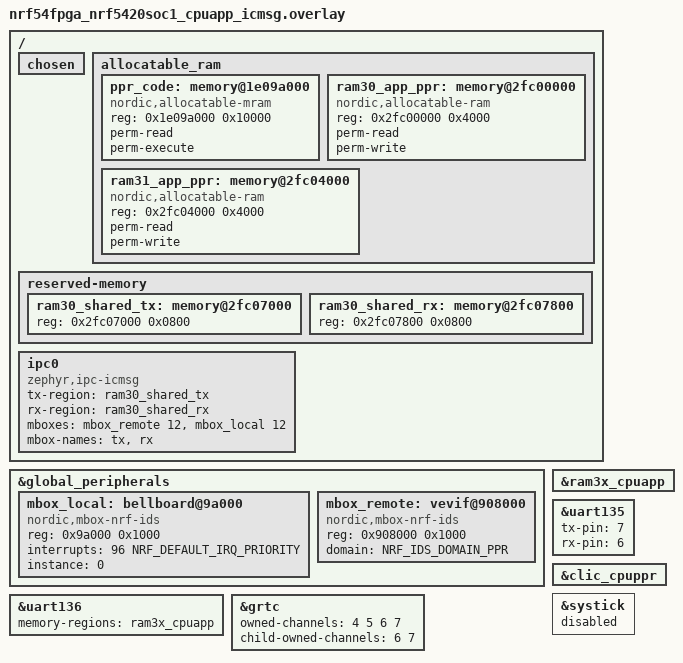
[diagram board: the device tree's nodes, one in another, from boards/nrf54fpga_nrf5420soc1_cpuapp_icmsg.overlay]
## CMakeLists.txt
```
#
# Copyright (c) 2022 Nordic Semiconductor
#
# SPDX-License-Identifier: LicenseRef-Nordic-5-Clause
#

cmake_minimum_required(VERSION 3.20.0)

if(CONF_FILE)
  if(${CONF_FILE} MATCHES "prj_(.*).conf")
    set(CONF_FILE_BUILD_TYPE ${CMAKE_MATCH_1})

    # At this stage, any revision attached to the board will not be available
    # as BOARD_REVISION, just "@<revision>" in the board name. We clean up the
    # path to reflect what the associated overlay/fragment paths are supposed to
    # look like in sample/boards.
    string(REPLACE "@" "_" SAMPLE_BOARD "${BOARD}")

    set(DTC_OVERLAY_FILE "${CMAKE_CURRENT_SOURCE_DIR}/boards/${SAMPLE_BOARD}_${CONF_FILE_BUILD_TYPE}.overlay")
  endif()
  set(remote_CONF_FILE ${CONF_FILE})
endif()

set(ZEPHYR_EXTRA_MODULES ${CMAKE_CURRENT_LIST_DIR})

find_package(Zephyr REQUIRED HINTS $ENV{ZEPHYR_BASE})
project(event_manager_proxy)

message(STATUS "Overlay set to: ${DTC_OVERLAY_FILE}")

add_subdirectory(common_events)
add_subdirectory(modules)

target_sources(app PRIVATE src/main.c)

if (CONFIG_SOC_PLATFORM_HALTIUM)
  build_secdom()
  build_sysctrl()
endif()
```

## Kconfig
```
#
# Copyright (c) 2022 Nordic Semiconductor ASA
#
# SPDX-License-Identifier: LicenseRef-Nordic-5-Clause
#

menu "Zephyr Kernel"
source "Kconfig.zephyr"
endmenu

menu "Event manager proxy sample application settings"

config APP_EVENT_MANAGER_REMOTE_WAIT_TO
	int "Waiting period for the remote core to finish the initialization"
	range 10 5000
	default 1000
	help
	  The time to wait for second core to report its readines to transport the events.
	  The time is given in miliseconds.

config APP_INCLUDE_REMOTE_IMAGE
	bool "Include remote image as sub image"
	depends on SOC_NRF5340_CPUAPP || SOC_NRF54H20_CPUAPP || SOC_NRF9230_CPUAPP
	default y if (BOARD_NRF5340DK_NRF5340_CPUAPP || BOARD_NRF5340DK_NRF5340_CPUAPP_NS || BOARD_NRF54H20DK_NRF54H20_CPUAPP || BOARD_NRF9230DK_NRF9230_CPUAPP)
	select PARTITION_MANAGER_ENABLED if SOC_NRF5340_CPUAPP
	select BOARD_ENABLE_CPUNET if (BOARD_NRF5340DK_NRF5340_CPUAPP || BOARD_NRF5340DK_NRF5340_CPUAPP_NS)

config APP_REMOTE_BOARD
	string "The name of the CORE to be used by remote image"
	depends on APP_INCLUDE_REMOTE_IMAGE
	default DOMAIN_CPUNET_BOARD if (BOARD_NRF5340DK_NRF5340_CPUAPP || BOARD_NRF5340DK_NRF5340_CPUAPP_NS)
	default "nrf54h20dk_nrf54h20_cpuppr@soc1" if (BOARD_NRF54H20DK_NRF54H20_CPUAPP && HW_REVISION_SOC1)
	default "nrf9230dk_nrf9230_cpuppr" if (BOARD_NRF9230DK_NRF9230_CPUAPP)

rsource "common_events/Kconfig"
rsource "modules/Kconfig"
endmenu
```

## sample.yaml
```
sample:
  description: Sample showing usage of sending the events to another core via Event Manager Proxy
  name: Event Manager proxy sample
tests:
  sample.event_manager_proxy:
    build_only: true
    platform_allow: nrf5340dk_nrf5340_cpuapp
    integration_platforms:
      - nrf5340dk_nrf5340_cpuapp
    tags: ci_build
  sample.event_manager_proxy.icmsg:
    build_only: true
    platform_allow: nrf5340dk_nrf5340_cpuapp
    integration_platforms:
      - nrf5340dk_nrf5340_cpuapp
    tags: ci_build
    extra_args: CONF_FILE=prj_icmsg.conf
  sample.event_manager_proxy.nrf54h20.fpga.icmsg:
    build_only: true
    platform_allow: nrf54h20dk_nrf54h20_cpuapp@soc1
    integration_platforms:
      - nrf54h20dk_nrf54h20_cpuapp@soc1
    tags: ci_build
    extra_args: CONF_FILE=prj_icmsg.conf remote_CONFIG_EMULATOR_FPGA=y
    extra_configs:
      - CONFIG_EMULATOR_FPGA=y
  sample.event_manager_proxy.nrf54h20.icmsg:
    build_only: true
    platform_allow: nrf54h20dk_nrf54h20_cpuapp@soc1
    integration_platforms:
      - nrf54h20dk_nrf54h20_cpuapp@soc1
    tags: ci_build
    extra_args: CONF_FILE=prj_icmsg.conf
  sample.event_manager_proxy.nrf9230.fpga.icmsg:
    build_only: true
    platform_allow: nrf9230dk_nrf9230_cpuapp
    integration_platforms:
      - nrf9230dk_nrf9230_cpuapp
    tags: ci_build
    extra_args: CONF_FILE=prj_icmsg.conf remote_CONFIG_EMULATOR_FPGA=y
    extra_configs:
      - CONFIG_EMULATOR_FPGA=y
```

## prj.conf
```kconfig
#
# Copyright (c) 2022 Nordic Semiconductor ASA
#
# SPDX-License-Identifier: LicenseRef-Nordic-5-Clause
#
# Enabling assert
CONFIG_ASSERT=y

# Logger configuration
CONFIG_SERIAL=y
CONFIG_CONSOLE=y
CONFIG_LOG=y
CONFIG_LOG_DEFAULT_LEVEL=2
CONFIG_LOG_BACKEND_UART=y

# Configuration required by Event Manager
CONFIG_APP_EVENT_MANAGER=y
CONFIG_EVENT_MANAGER_PROXY=y
CONFIG_HEAP_MEM_POOL_SIZE=4096
CONFIG_REBOOT=y

CONFIG_PRINTK=y

CONFIG_IPC_SERVICE=y
CONFIG_MBOX=y

CONFIG_OPENAMP=y
CONFIG_OPENAMP_SLAVE=n

# Simplify debugging
CONFIG_RESET_ON_FATAL_ERROR=n

###################################
# Application configuration
###################################

CONFIG_APP_CONFIG_EVENT=y
CONFIG_APP_MODULE_STATS_ENABLE=y
```

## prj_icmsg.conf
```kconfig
#
# Copyright (c) 2022 Nordic Semiconductor ASA
#
# SPDX-License-Identifier: LicenseRef-Nordic-5-Clause
#
# Enabling assert
CONFIG_ASSERT=y

# Logger configuration
CONFIG_SERIAL=y
CONFIG_CONSOLE=y
CONFIG_LOG=y
CONFIG_LOG_DEFAULT_LEVEL=2
CONFIG_LOG_BACKEND_UART=y

# Configuration required by Event Manager
CONFIG_APP_EVENT_MANAGER=y
CONFIG_EVENT_MANAGER_PROXY=y
CONFIG_HEAP_MEM_POOL_SIZE=4096
CONFIG_REBOOT=y

CONFIG_PRINTK=y

CONFIG_IPC_SERVICE=y
CONFIG_MBOX=y

# Simplify debugging
CONFIG_RESET_ON_FATAL_ERROR=n

###################################
# Application configuration
###################################

CONFIG_APP_CONFIG_EVENT=y
CONFIG_APP_MODULE_STATS_ENABLE=y
```

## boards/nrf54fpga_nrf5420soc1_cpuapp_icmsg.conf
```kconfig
#
# Copyright (c) 2022 Nordic Semiconductor ASA
#
# SPDX-License-Identifier: LicenseRef-Nordic-5-Clause
#

CONFIG_MBOX_NRFX_IDS=y
CONFIG_NRF_REGTOOL_TOML_CONFIG_FILES="uicr/nrf54fpga_nrf5420_cpuapp.toml"

# Higher timouts are required.
CONFIG_EVENT_MANAGER_PROXY_BIND_TIMEOUT_MS=4000
```

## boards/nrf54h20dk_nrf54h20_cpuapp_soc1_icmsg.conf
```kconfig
#
# Copyright (c) 2022 Nordic Semiconductor ASA
#
# SPDX-License-Identifier: LicenseRef-Nordic-5-Clause
#

CONFIG_MBOX_NRFX_IDS=y

# Higher timouts are required.
CONFIG_EVENT_MANAGER_PROXY_BIND_TIMEOUT_MS=4000

CONFIG_UART_CONSOLE=y
CONFIG_CONSOLE=y
CONFIG_SERIAL=y
```

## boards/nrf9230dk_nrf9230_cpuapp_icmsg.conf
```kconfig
#
# Copyright (c) 2023 Nordic Semiconductor ASA
#
# SPDX-License-Identifier: LicenseRef-Nordic-5-Clause
#

CONFIG_MBOX_NRFX_IDS=y

# Higher timouts are required.
CONFIG_EVENT_MANAGER_PROXY_BIND_TIMEOUT_MS=4000

CONFIG_UART_CONSOLE=y
CONFIG_CONSOLE=y
CONFIG_SERIAL=y
```

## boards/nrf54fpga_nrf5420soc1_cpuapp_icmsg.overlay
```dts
/*
 * Copyright (c) 2022 Nordic Semiconductor ASA
 *
 * SPDX-License-Identifier: LicenseRef-Nordic-5-Clause
 */

/ {
	chosen {
		/delete-property/ nordic,bellboard-cpuapp;
		/delete-property/ nordic,vevif-cpuppr;
	};

	allocatable_ram {
		#address-cells = <1>;
		#size-cells = <1>;

		/* Configure PPR code region. Allow to execute from defined
		 * region by App and cores owned by App.
		 */
		ppr_code: memory@1e09a000 {
			compatible = "nordic,allocatable-mram";
			reg = <0x1e09a000 0x10000>;
			perm-read;
			perm-execute;
		};

		/* Configure PPR memory region. Allow to use defined RAM
		 * region by App and cores owned by App.
		 */
		ram30_app_ppr: memory@2fc00000 {
			compatible = "nordic,allocatable-ram";
			reg = <0x2fc00000 0x4000>;
			perm-read;
			perm-write;
		};

		/* Configure PPR memory region. Allow to use defined RAM
		 * region by App and cores owned by App.
		 */
		ram31_app_ppr: memory@2fc04000 {
			compatible = "nordic,allocatable-ram";
			reg = <0x2fc04000 0x4000>;
			perm-read;
			perm-write;
		};
	};

	reserved-memory {
		ram30_shared_tx: memory@2fc07000 {
			reg = <0x2fc07000 0x0800>;
		};

		ram30_shared_rx: memory@2fc07800 {
			reg = <0x2fc07800 0x0800>;
		};
	};

	ipc0: ipc0 {
		compatible = "zephyr,ipc-icmsg";
		tx-region = <&ram30_shared_tx>;
		rx-region = <&ram30_shared_rx>;
		mboxes = <&mbox_remote 12>,
			 <&mbox_local  12>;
		mbox-names = "tx", "rx";
		status = "okay";
	};
};

&global_peripherals {
	/* Delete and redefine nodes with custom compatible. */
	/delete-node/ bellboard@9a000;
	/delete-node/ vevif@8c8000; /* SYSCtrl */
	/delete-node/ vevif@8d4000; /* FLPR */
	/delete-node/ vevif@908000; /* PPR */

	mbox_local: bellboard@9a000 {
		compatible = "nordic,mbox-nrf-ids";
		status = "okay";
		reg = <0x9a000 0x1000>;
		interrupts = <96 NRF_DEFAULT_IRQ_PRIORITY>;
		instance = <0>;
		#mbox-cells = <1>;
	};

	mbox_remote: vevif@908000 {
		compatible = "nordic,mbox-nrf-ids";
		status = "okay";
		reg = <0x908000 0x1000>;
		domain = <NRF_IDS_DOMAIN_PPR>; /* Remote vevif belong to CPU PPR */
		#mbox-cells = <1>;
	};
};

/* ram3x_cpuapp buffer is used by App core UART driver. */
&ram3x_cpuapp {
	status = "okay";
};

&uart136 {
	status = "okay";
	memory-regions = <&ram3x_cpuapp>;
};

&uart135 {
	status = "okay";
	tx-pin = <7>;
	rx-pin = <6>;
};

&grtc {
	status = "okay";
	/* Channels 4 and 5 are used by the app core itself, channels 6 and 7
	 * are owned by App but used by PPR.
	 */
	owned-channels = <4 5 6 7>;
	child-owned-channels = <6 7>;
};

/* Enable PPR clic so App could start PPR. */
&clic_cpuppr {
	status = "okay";
};

/* Disable systick for App core, GRTC is used as tick source. */
&systick {
	status = "disabled";
};
```

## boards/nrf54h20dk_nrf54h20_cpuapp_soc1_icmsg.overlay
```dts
/*
 * Copyright (c) 2022 Nordic Semiconductor ASA
 *
 * SPDX-License-Identifier: LicenseRef-Nordic-5-Clause
 */

 / {
	chosen {
		zephyr,console = &uart136;
	};

	allocatable_ram {
		#address-cells = <1>;
		#size-cells = <1>;

		/* Configure PPR memory region. Allow to use defined RAM3x
		 * region by App and cores owned by App.
		 */
		ram3x_app_ppr: memory@2fc00000 {
			compatible = "nordic,allocatable-ram";
			reg = <0x2fc00000 DT_SIZE_K(32)>;
			perm-read;
			perm-write;
		};
	};
};

&cpuppr {
	loader-img-dst = <&ppr_code>;
	status = "okay";
};

&vevif_cpuppr {
       status = "okay";
};

ipc0: &ipc_to_cpuppr {
	status = "okay";
};

/* ram3x_cpuapp buffer is used by App core UART driver. */
&ram3x_cpuapp {
	status = "okay";
};

&uart136 {
	status = "okay";
	memory-regions = <&ram3x_cpuapp>;
};

&uart135 {
	status = "reserved";
};

&grtc {
	status = "okay";
};

/* Disable systick for App core, GRTC is used as tick source. */
&systick {
	status = "disabled";
};
```

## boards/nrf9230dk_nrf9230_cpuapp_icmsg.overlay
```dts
/*
 * Copyright (c) 2023 Nordic Semiconductor ASA
 *
 * SPDX-License-Identifier: LicenseRef-Nordic-5-Clause
 */

 / {
	chosen {
		zephyr,console = &uart136;
	};

	allocatable_ram {
		#address-cells = <1>;
		#size-cells = <1>;

		/* Configure PPR memory region. Allow to use defined RAM3x
		 * region by App and cores owned by App.
		 */
		ram3x_app_ppr: memory@2fc00000 {
			compatible = "nordic,allocatable-ram";
			reg = <0x2fc00000 DT_SIZE_K(32)>;
			perm-read;
			perm-write;
		};
	};
};

&cpuppr {
	loader-img-dst = <&ppr_code>;
	status = "okay";
};

&vevif_cpuppr {
       status = "okay";
};

ipc0: &ipc_to_cpuppr {
	status = "okay";
};

/* ram3x_cpuapp buffer is used by App core UART driver. */
&ram3x_cpuapp {
	status = "okay";
};

&uart136 {
	status = "okay";
	memory-regions = <&ram3x_cpuapp>;
};

&uart135 {
	status = "reserved";
};
```

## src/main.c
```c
/*
 * Copyright (c) 2022 Nordic Semiconductor ASA
 *
 * SPDX-License-Identifier: LicenseRef-Nordic-5-Clause
 */

#include <zephyr/kernel.h>
#include <zephyr/device.h>

#include <zephyr/ipc/ipc_service.h>

#include <app_event_manager.h>
#include <event_manager_proxy.h>
#include <config_event.h>
#include <control_event.h>
#include <measurement_event.h>
#include <zephyr/logging/log.h>

#define MODULE main

LOG_MODULE_REGISTER(MODULE);

#define INIT_VALUE1 3

#if defined(CONFIG_BOARD_NRF54H20DK_NRF54H20_CPUAPP)
#define PPR_START_ADDR DT_REG_ADDR(DT_NODELABEL(ppr_code))
#include <hal/nrf_vpr.h>
#endif

int main(void)
{
#if defined(CONFIG_BOARD_NRF54H20DK_NRF54H20_CPUAPP)
	/* Enable PPR core */
	nrf_vpr_initpc_set(NRF_VPR130, PPR_START_ADDR);
	nrf_vpr_cpurun_set(NRF_VPR130, true);
#endif
	int ret;
	const struct device *ipc_instance  = DEVICE_DT_GET(DT_NODELABEL(ipc0));

	printk("Event Manager Proxy demo started\n");
	LOG_INF("Starting");

	ret = app_event_manager_init();
	if (ret) {
		LOG_ERR("Event Manager not initialized, err: %d", ret);
		__ASSERT_NO_MSG(false);
		return 0;
	}
	LOG_INF("Event manager initialized");

	ret = event_manager_proxy_add_remote(ipc_instance);
	if (ret && ret != -EALREADY) {
		LOG_ERR("Cannot add remote: %d", ret);
		__ASSERT_NO_MSG(false);
		return 0;
	}
	LOG_INF("Event proxy remote added");

	/* Listen to the events from the remote */
	ret = EVENT_MANAGER_PROXY_SUBSCRIBE(ipc_instance, control_event);
	if (ret) {
		LOG_ERR("Cannot register to remote control_event: %d", ret);
		__ASSERT_NO_MSG(false);
		return 0;
	}
	LOG_INF("Event proxy control_event registered");
	ret = EVENT_MANAGER_PROXY_SUBSCRIBE(ipc_instance, measurement_event);
	if (ret) {
		LOG_ERR("Cannot register to remote measurement_event: %d", ret);
		__ASSERT_NO_MSG(false);
		return 0;
	}
	LOG_INF("Event proxy measurement_event registered");

	ret = event_manager_proxy_start();
	if (ret) {
		LOG_ERR("Cannot start event manager proxy: %d", ret);
		__ASSERT_NO_MSG(false);
		return 0;
	}
	LOG_INF("Event manager proxy started");

	/* Wait for all the remote cores to finish event proxy initialization */
	ret = event_manager_proxy_wait_for_remotes(K_MSEC(CONFIG_APP_EVENT_MANAGER_REMOTE_WAIT_TO));
	if (ret) {
		LOG_ERR("Error when waiting for remote: %d", ret);
		__ASSERT_NO_MSG(false);
		return 0;
	}
	LOG_INF("All remotes ready");

	/* Sending config event that should be received and processed by the remote */
	struct config_event *event = new_config_event();

	event->init_value1 = INIT_VALUE1;
	APP_EVENT_SUBMIT(event);

	LOG_INF("Initialization finished successfully");

	/* Main is not needed anymore - rest would be processed in events in stats module */
	return 0;
}
```
